AUTOSAR XML (schema 4-0-3)
standard types defined: Boolean, UInt8
package /AUTOSAR_Platform/DataConstrs
  range DC_UInt8: raw 0..255
package /PATAC/Facility/DataTypes/Implementation
  unit NoUnit: factor-si-to-unit=1, offset-si-to-unit=0
package /PATAC/MSM/ComponentTypes
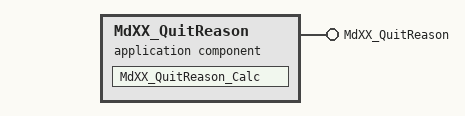
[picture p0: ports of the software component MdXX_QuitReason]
  application sw component type MdXX_QuitReason
    provide port MdXX_QuitReason: server-com-spec{operation=Calc, queue-length=1}, provided-interface=MdXX_QuitReason
    behavior MdXX_QuitReason_InternalBehavior
      operation invoked event OIT_MdXX_QuitReason_Calc_MdXX_QuitReason_Calc: start-on-event=MdXX_QuitReason_Calc, operation=MdXX_QuitReason.Calc
      runnable MdXX_QuitReason_Calc
  swc implementation MdXX_QuitReason_Implementation: behavior=MdXX_QuitReason_InternalBehavior
    code-descriptors:
      code Default: artifact-descriptors=autosar-engineering-object={short-label=Default, category=SWSRC}
package /PATAC/MSM/ModeAdjust/DataType
  impl type MdRspLocal2: category=VALUE, base-type=UInt8, sw-calibration-access=READ-ONLY, compu {0=MdRsp_None, 1=MdRsp_RecallSuccessfully, 2=MdRsp_RecallUnsuccessfully_LocalInterrupt, 3=MdRsp_RecallUnsuccessfully_NonEnghSpace, 4=MdRsp_RecallOngoing, 5=MdRsp_TargetPositionAlready, 6=MdRsp_LowPower, 7=MdRsp_CrashStat, 8=MdRsp_ThdRwOccupt, 9=MdRsp_PosNotLrn, 10=MdRsp_NotParkStat, 11=MdRsp_SpdNotCorrt}, type-emitter=RTE
package /PATAC/MSM/ModeAdjust/PortInterface
  client server interface MdXX_QuitReason
    operation Calc
      5 x arg, all with server-argument-impl-policy=USE-ARGUMENT-TYPE:
        MdDone: type=UInt8, direction=IN
        ExitCond: type=Boolean, direction=IN
        SWInt: type=Boolean, direction=IN
        SoftInt: type=Boolean, direction=IN
        MdQuitReason: type=MdRspLocal2, direction=OUT
